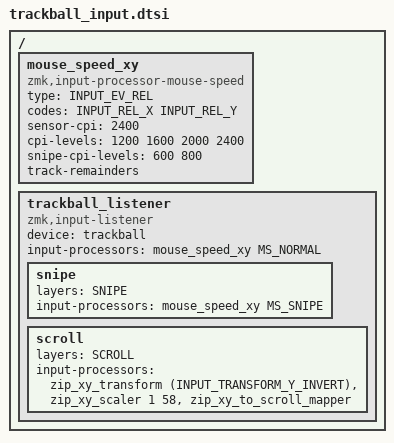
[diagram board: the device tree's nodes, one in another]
#include <dt-bindings/zmk/input_transform.h>
#include <input/processors.dtsi>

// Layer indexes, as in config/mona2.keymap
#define NONE	0
#define DEFAULT	0
#define COLEMAK	1
#define LOWER	2
#define RAISE	3
#define ADJUST	4
#define MOUSE   5
#define SCROLL  6
#define SNIPE   7
#define TEST	8

// Speed level sets of &mouse_speed and mouse_speed_xy (src/mouse_speed.c)
#define MS_NORMAL	0
#define MS_SNIPE	1

/ {
  // Runs the trackball at the CPI of the speed level picked with &mouse_speed (src/mouse_speed.c).
  // The levels are the Charybdis QMK DPI steps: CHARYBDIS_MINIMUM_DEFAULT_DPI 1200 plus
  // CHARYBDIS_DEFAULT_DPI_CONFIG_STEP 400, four steps; sniping CHARYBDIS_MINIMUM_SNIPING_DPI 600
  // plus CHARYBDIS_SNIPING_DPI_CONFIG_STEP 200, two steps.
  mouse_speed_xy: mouse_speed_xy {
    compatible = "zmk,input-processor-mouse-speed";
    #input-processor-cells = <1>;
    type = <INPUT_EV_REL>;
    codes = <INPUT_REL_X INPUT_REL_Y>;
    sensor-cpi = <2400>;                      // res-cpi in mona2_paw3222.dtsi
    cpi-levels = <1200 1600 2000 2400>;
    snipe-cpi-levels = <600 800>;
    track-remainders;
  };

  trackball_listener: trackball_listener {
    compatible = "zmk,input-listener";
    device = <&trackball>;

    input-processors = <&mouse_speed_xy MS_NORMAL>;

    // Holding Snipe runs at the sniping level's CPI, stepped with &mouse_speed MS_SNIPE
    snipe {
      layers = <SNIPE>;
      input-processors = <&mouse_speed_xy MS_SNIPE>;
    };

    // The ball becomes a scroll wheel; rolling it towards you scrolls down.
    // 1/58 of the raw ball movement at res-cpi 2400; raise the divisor to scroll slower.
    scroll {
      layers = <SCROLL>;
      input-processors = <
        &zip_xy_transform (INPUT_TRANSFORM_Y_INVERT)
        &zip_xy_scaler 1 58
        &zip_xy_to_scroll_mapper
      >;
    };
  };
};
